CM_ "IMPORT _comma.dbc";
CM_ "IMPORT _honda_common.dbc";
CM_ "IMPORT _nidec_common.dbc";
CM_ "IMPORT _steering_sensors_b.dbc";

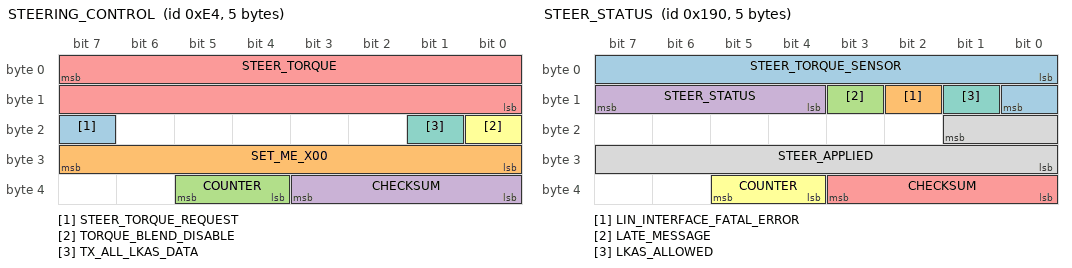
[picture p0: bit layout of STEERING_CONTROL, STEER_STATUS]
BO_ 228 STEERING_CONTROL: 5 ADAS
 SG_ STEER_TORQUE_REQUEST : 23|1@0+ (1,0) [0|1] "" EPS
 SG_ SET_ME_X00 : 31|8@0+ (1,0) [0|0] "" EPS
 SG_ COUNTER : 37|2@0+ (1,0) [0|3] "" EPS
 SG_ CHECKSUM : 35|4@0+ (1,0) [0|3] "" EPS
 SG_ STEER_TORQUE : 7|16@0- (1,0) [-3840|3840] "" EPS
 SG_ TORQUE_BLEND_DISABLE : 16|1@0+ (1,0) [0|1] "" XXX
 SG_ TX_ALL_LKAS_DATA : 17|1@0+ (1,0) [0|1] "" XXX

BO_ 400 STEER_STATUS: 5 EPS
 SG_ STEER_TORQUE_SENSOR : 0|9@1- (1,0) [-256|256] "" XXX
 SG_ LIN_INTERFACE_FATAL_ERROR : 10|1@0+ (1,0) [0|1] "" XXX
 SG_ LATE_MESSAGE : 11|1@0+ (1,0) [0|1] "" XXX
 SG_ STEER_STATUS : 12|4@1+ (1,0) [0|15] "" XXX
 SG_ CHECKSUM : 35|4@0+ (1,0) [0|3] "" EON
 SG_ COUNTER : 37|2@0+ (1,0) [0|3] "" XXX
 SG_ LKAS_ALLOWED : 9|1@0+ (1,0) [0|1] "" XXX
 SG_ STEER_APPLIED : 17|10@0+ (1,0) [0|511] "" XXX

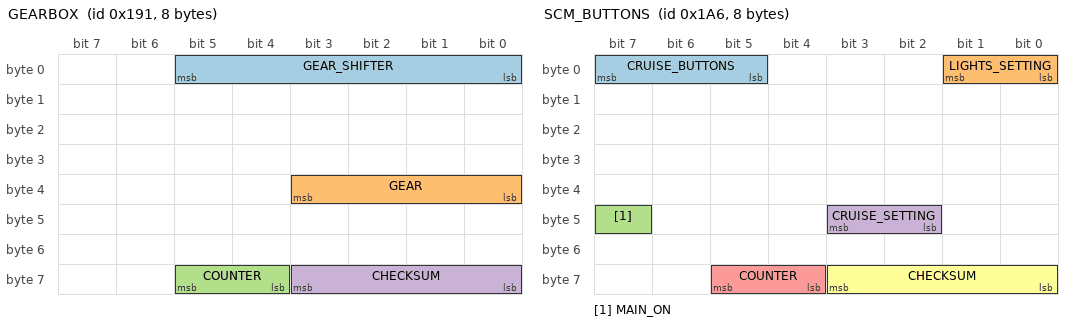
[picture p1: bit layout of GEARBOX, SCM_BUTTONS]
BO_ 401 GEARBOX: 8 PCM
 SG_ GEAR_SHIFTER : 5|6@0+ (1,0) [0|63] "" NEO
 SG_ GEAR : 35|4@0+ (1,0) [0|15] "" NEO
 SG_ COUNTER : 61|2@0+ (1,0) [0|3] "" NEO
 SG_ CHECKSUM : 59|4@0+ (1,0) [0|15] "" NEO

BO_ 422 SCM_BUTTONS: 8 SCM
 SG_ CRUISE_BUTTONS : 7|3@0+ (1,0) [0|7] "" NEO
 SG_ LIGHTS_SETTING : 1|2@0+ (1,0) [0|3] "" NEO
 SG_ MAIN_ON : 47|1@0+ (1,0) [0|1] "" NEO
 SG_ CRUISE_SETTING : 43|2@0+ (1,0) [0|3] "" NEO
 SG_ COUNTER : 61|2@0+ (1,0) [0|3] "" NEO
 SG_ CHECKSUM : 59|4@0+ (1,0) [0|15] "" NEO

BO_ 520 SS_STATUS: 3 XXX
 SG_ VERSION_NUM : 0|4@1+ (1,0) [0|15] "" XXX
 SG_ HARDWARE_REV : 7|4@0+ (1,0) [0|15] "" XXX
 SG_ LATE_SERIAL_MSG : 8|1@0+ (1,0) [0|1] "" XXX
 SG_ LATE_CAN_MSG : 9|1@0+ (1,0) [0|1] "" XXX
 SG_ INVALID_COUNTER : 10|1@0+ (1,0) [0|1] "" XXX
 SG_ INVALID_CHECKSUM : 11|1@0+ (1,0) [0|1] "" XXX
 SG_ LKAS_ALLOWED : 12|1@0+ (1,0) [0|1] "" XXX
 SG_ CHECKSUM : 16|4@1+ (1,0) [0|15] "" XXX
 SG_ COUNTER : 21|3@0+ (1,0) [0|3] "" XXX

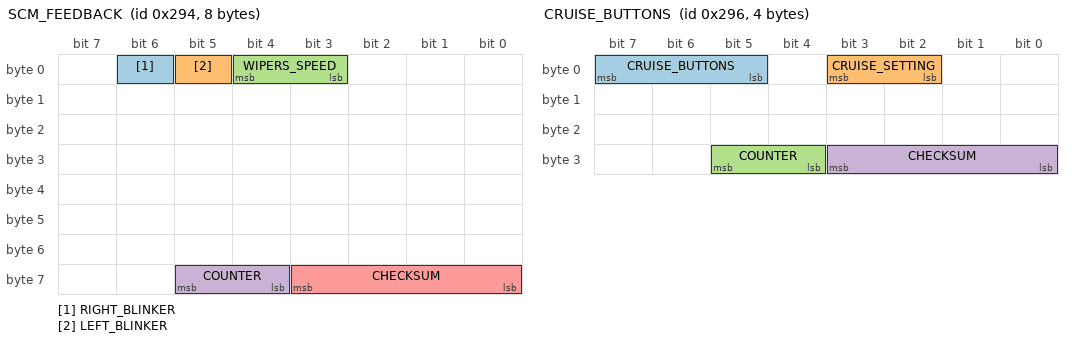
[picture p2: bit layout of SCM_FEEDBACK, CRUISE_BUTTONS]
BO_ 660 SCM_FEEDBACK: 8 SCM
 SG_ RIGHT_BLINKER : 6|1@0+ (1,0) [0|1] "" NEO
 SG_ LEFT_BLINKER : 5|1@0+ (1,0) [0|1] "" NEO
 SG_ WIPERS_SPEED : 4|2@0+ (1,0) [0|3] "" NEO
 SG_ COUNTER : 61|2@0+ (1,0) [0|3] "" XXX
 SG_ CHECKSUM : 59|4@0+ (1,0) [0|15] "" XXX

BO_ 662 CRUISE_BUTTONS: 4 SCM
 SG_ CRUISE_BUTTONS : 7|3@0+ (1,0) [0|7] "" NEO
 SG_ CRUISE_SETTING : 3|2@0+ (1,0) [0|3] "" NEO
 SG_ COUNTER : 29|2@0+ (1,0) [0|3] "" XXX
 SG_ CHECKSUM : 27|4@0+ (1,0) [0|15] "" XXX

BO_ 927 ACC_HUD_2: 8 ADAS
 SG_ ZEROS_BOH : 7|17@0+ (1,0) [0|127] "" BDY
 SG_ APPLY_BRAKES_FOR_CANC : 23|1@0+ (1,0) [0|15] "" BDY
 SG_ ZEROS_BOH2 : 31|8@0+ (1,0) [0|127] "" BDY
 SG_ RESUME_INSTRUCTION : 21|1@0+ (1,0) [0|15] "" BDY
 SG_ ACC_ALERTS : 20|5@0+ (1,0) [0|15] "" BDY
 SG_ LEAD_SPEED : 39|9@0+ (1,0) [0|127] "" BDY
 SG_ LEAD_STATE : 46|3@0+ (1,0) [0|127] "" BDY
 SG_ LEAD_DISTANCE : 43|5@0+ (1,0) [0|31] "" BDY
 SG_ ZEROS_BOH3 : 54|7@0+ (1,0) [0|127] "" BDY
 SG_ COUNTER : 61|2@0+ (1,0) [0|3] "" XXX
 SG_ CHECKSUM : 59|4@0+ (1,0) [0|15] "" XXX

VAL_ 400 STEER_STATUS 6 "tmp_fault" 5 "fault_1" 4 "no_torque_alert_2" 3 "low_speed_lockout" 2 "no_torque_alert_1" 0 "normal" ;
VAL_ 401 GEAR_SHIFTER 32 "L" 16 "S" 8 "D" 4 "N" 2 "R" 1 "P" ;
CM_ "CHFFR_METRIC 342 STEER_ANGLE STEER_ANGLE 0.36 180; CHFFR_METRIC 380 ENGINE_RPM ENGINE_RPM 1 0; CHFFR_METRIC 804 ENGINE_TEMPERATURE ENGINE_TEMPERATURE 1 0";
